# cslr_tcp2_config_bus register map
Vendor: Texas Instruments
Peripheral module from a debugger description file.
Registers are 32-bit, access not given, reset 0x0 unless marked. A register's access mark holds for its fields unless they carry their own. Offsets are as the file gives them; lines under a group give offsets from that group; [hi:lo] are bit positions; {n}, {i} and the like mark numbered series; 'fields as' and 'values as' point back to an identical list; <NAME> marks a mode.

## TCP2 — Turbo-decoder Coprocessor (TCP) has designed to meet requirement of high bit rate data decoding as in IS2000 and 3GPP wireless standards.TCP provides very low processing delay because of the highly paralleled architechure. Processing delay can be further reduced by enabling stopping criteria algorithm. TCP reduces board space and power consumption by performing turbo decoding on-chip. TCP is high flexibility to cope with standard evolutions. Accepts any frame length from 40 (3GPP minimum frame size) up to 20730 (IS2000 maximum frame size).
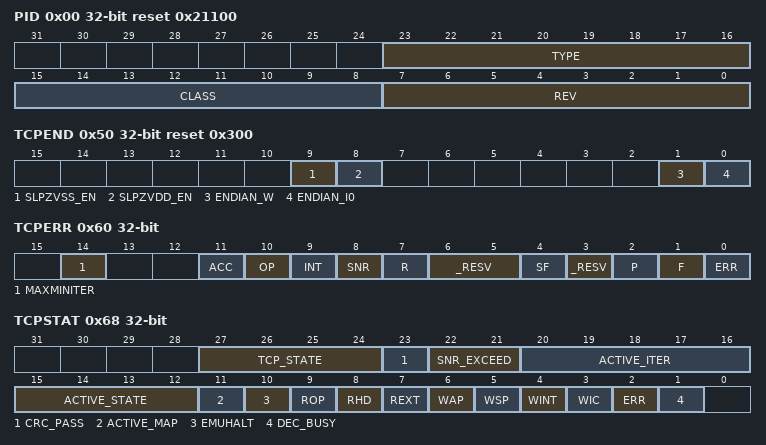
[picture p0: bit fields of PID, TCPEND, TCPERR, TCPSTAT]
0x00 PID reset 0x21100 (reset mask 0xFFFFFF00) — PID contains the ID and ID revision of the peripheral.
  [23:16] TYPE ro — Peripheral type
  [15:8] CLASS ro — Identifies the peripheral class
  [7:0] REV ro — Peripheral revision
0x4C TCPEXE wo — TCPEXE is an execution register
  [2:0] EXECUTION_INSTR — Execution instruction
    0=NO (No instruction); 1=START (Start TCP); 4=DEBUG0 (Debug mode; Normal initialization's and wait in MAP state 0); 5=DEBUG6 (Debug mode; execute one MAP decode and wait in MAP state 6); 6=DEBUG (Debug mode; execute remaining MAP decodes and complete normal ending); 7=SOFTRESET (Soft reset all TCP registers except for the execution register, Indian register and other internal registers)
0x50 TCPEND reset 0x300 — TCPEND should only be used when the DSP is set to big-endian mode
  [9] SLPZVSS_EN rw — Enable internal control of slpzvss
    0=DISABLE (Disable sleep mode); 1=ENABLE (Enable internal control of SLPZVSS)
  [8] SLPZVDD_EN rw — Enable internal control of slpzvdd
    0=DISABLE (Disable sleep mode); 1=ENABLE (Enable internal control of SLPZVDD)
  [1] ENDIAN_W rw — Endianess view of extrinsic data
    0=32BITS (Packed on 32 bits); 1=NATIVE8 (8 bits native format)
  [0] ENDIAN_I0 rw — Endianess view of interleaver table
    0=32BITS (Packed on 32 bits); 1=NATIVE16 (16 bits native format)
0x60 TCPERR — TCPERR provided error status of TCP
  [14] MAXMINITER ro — Maximum / minimum iteration error
  [11] ACC ro — Spurious TCP memory access
  [10] OP ro — Output parameters load for shared processing
  [9] INT ro — Interleaver table load for shared processing
  [8] SNR ro — SNR Threshold Check
  [7] R ro — Reliability Length
  [6:5] _RESV — (access N)
  [4] SF ro — Sub-frame length
  [3] _RESV — (access N)
  [2] P ro — Prolog length
  [1] F ro — Frame length
  [0] ERR ro — Error Status
0x68 TCPSTAT — TCPSTAT provided status of TCP
  [27:24] TCP_STATE ro — TCP top level state of the state machine
  [23] CRC_PASS ro — CRC Status
  [22:21] SNR_EXCEED ro — SNR status
    0=MAP01_FAIL (MAP0 failed SNR); 1=MAP0_PASS (MAP0 passed SNR); 2=MAP1_PASS (MAP1 passed SNR)
  [20:16] ACTIVE_ITER ro — Active iteration status
  [15:12] ACTIVE_STATE ro — Active MAP decoder state
  [11] ACTIVE_MAP ro — Active MAP status
    0=MAP0 (Processing MAP0); 1=MAP1 (Processing MAP1)
  [10] EMUHALT ro — Defines if the TCP is halt due to emulation
  [9] ROP ro — Defines if the TCP is waiting for output parameter data to be read
  [8] RHD ro — Defines if the TCP is waiting for hard decision data to be read
  [7] REXT ro — Defines if the TCP is waiting for w0 data to be read
  [6] WAP ro — Defines if the TCP is waiting for w1 data to be written
  [5] WSP ro — Defines if the TCP is waiting for systematic and parity data to be written
  [4] WINT ro — Defines if the TCP is waiting for interleaver indexes to be written
  [3] WIC ro — Defines if the TCP is waiting for input control words to be written.
  [2] ERR ro — Defines if the TCP has encountered an error
  [1] DEC_BUSY ro — Decoder status
    0=STATE0 (MAP decoder is in state 0); 1=STATE1_8 (MAP decoder is in state 1 to 8)
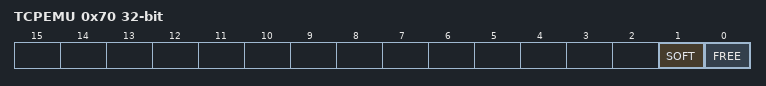
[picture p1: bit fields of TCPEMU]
0x70 TCPEMU — TCPEMU Emulation support helps in system debug.
  [1] SOFT rw — Programmable emulation mode
  [0] FREE rw
